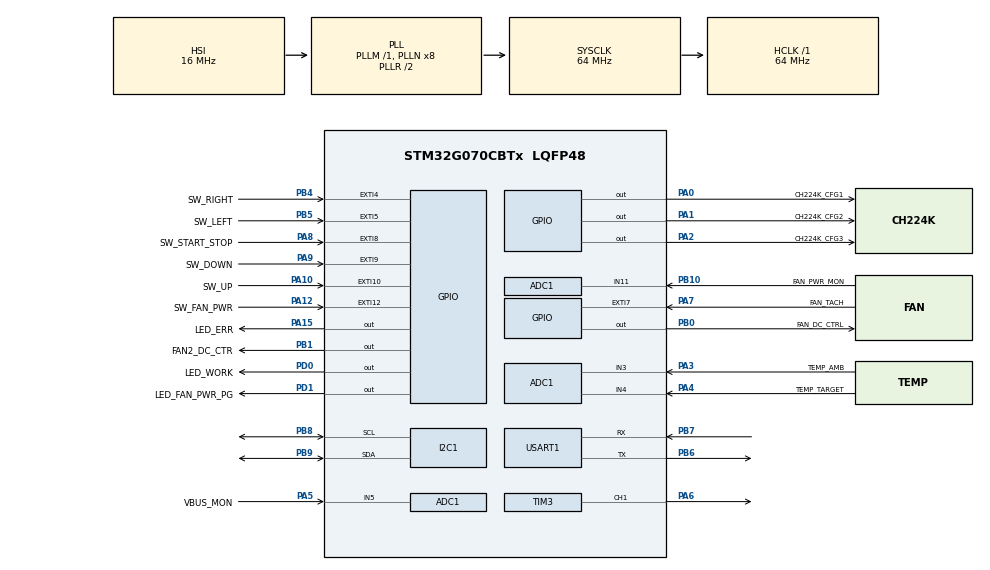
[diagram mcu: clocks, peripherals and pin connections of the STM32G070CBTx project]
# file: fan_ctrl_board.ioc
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ADC1.Channel-1\#ChannelRegularConversion=ADC_CHANNEL_3
ADC1.Channel-2\#ChannelRegularConversion=ADC_CHANNEL_4
ADC1.Channel-3\#ChannelRegularConversion=ADC_CHANNEL_5
ADC1.Channel-4\#ChannelRegularConversion=ADC_CHANNEL_11
ADC1.DiscontinuousConvMode=ENABLE
ADC1.NbrOfConversion=4
ADC1.NbrOfConversionFlag=1
ADC1.Rank-1\#ChannelRegularConversion=1
ADC1.Rank-2\#ChannelRegularConversion=2
ADC1.Rank-3\#ChannelRegularConversion=3
ADC1.Rank-4\#ChannelRegularConversion=4
ADC1.SamplingTime-1\#ChannelRegularConversion=ADC_SAMPLINGTIME_COMMON_1
ADC1.SamplingTime-2\#ChannelRegularConversion=ADC_SAMPLINGTIME_COMMON_1
ADC1.SamplingTime-3\#ChannelRegularConversion=ADC_SAMPLINGTIME_COMMON_1
ADC1.SamplingTime-4\#ChannelRegularConversion=ADC_SAMPLINGTIME_COMMON_1
ADC1.SelectedChannel=ADC_CHANNEL_3|ADC_CHANNEL_4|ADC_CHANNEL_5|ADC_CHANNEL_11
ADC1.master=1
I2C1.Timing=0x10707DBC
Mcu.Family=STM32G0
Mcu.Name=STM32G070CBTx
Mcu.Package=LQFP48
NVIC.ADC1_IRQn=true\:0\:0\:false\:false\:true\:true\:true\:true
NVIC.EXTI4_15_IRQn=true\:0\:0\:false\:false\:true\:true\:true\:true
NVIC.USART1_IRQn=true\:0\:0\:false\:false\:true\:true\:true\:true
PA0.GPIO_Label=CH224K_CFG1
PA0.PinState=GPIO_PIN_SET
PA0.Signal=GPIO_Output
PA1.GPIO_Label=CH224K_CFG2
PA1.Signal=GPIO_Output
PA10.GPIO_Label=SW_UP
PA10.GPIO_ModeDefaultEXTI=GPIO_MODE_IT_RISING_FALLING
PA10.Signal=GPXTI10
PA12\ [PA10].GPIO_Label=SW_FAN_PWR
PA12\ [PA10].GPIO_ModeDefaultEXTI=GPIO_MODE_IT_RISING_FALLING
PA12\ [PA10].Signal=GPXTI12
PA13.Mode=Serial_Wire
PA13.Signal=SYS_SWDIO
PA14-BOOT0.Mode=Serial_Wire
PA14-BOOT0.Signal=SYS_SWCLK
PA15.GPIO_Label=LED_ERR
PA15.Signal=GPIO_Output
PA2.GPIO_Label=CH224K_CFG3
PA2.Signal=GPIO_Output
PA3.GPIO_Label=TEMP_AMB
PA3.Mode=IN3
PA3.Signal=ADC1_IN3
PA4.GPIO_Label=TEMP_TARGET
PA4.Mode=IN4
PA4.Signal=ADC1_IN4
PA5.GPIO_Label=VBUS_MON
PA5.Mode=IN5
PA5.Signal=ADC1_IN5
PA6.Signal=S_TIM3_CH1
PA7.GPIO_Label=FAN_TACH
PA7.GPIO_ModeDefaultEXTI=GPIO_MODE_IT_FALLING
PA7.Signal=GPXTI7
PA8.GPIO_Label=SW_START_STOP 
PA8.GPIO_ModeDefaultEXTI=GPIO_MODE_IT_RISING_FALLING
PA8.Signal=GPXTI8
PA9.GPIO_Label=SW_DOWN
PA9.GPIO_ModeDefaultEXTI=GPIO_MODE_IT_RISING_FALLING
PA9.Signal=GPXTI9
PB0.GPIO_Label=FAN_DC_CTRL
PB0.Signal=GPIO_Output
PB1.GPIO_Label=FAN2_DC_CTR
PB1.Signal=GPIO_Output
PB10.GPIO_Label=FAN_PWR_MON
PB10.Mode=IN11
PB10.Signal=ADC1_IN11
PB4.GPIO_Label=SW_RIGHT
PB4.GPIO_ModeDefaultEXTI=GPIO_MODE_IT_RISING_FALLING
PB4.GPIO_PuPd=GPIO_PULLUP
PB4.Signal=GPXTI4
PB5.GPIO_Label=SW_LEFT
PB5.GPIO_ModeDefaultEXTI=GPIO_MODE_IT_RISING_FALLING
PB5.GPIO_PuPd=GPIO_PULLUP
PB5.Signal=GPXTI5
PB6.Mode=Asynchronous
PB6.Signal=USART1_TX
PB7.Mode=Asynchronous
PB7.Signal=USART1_RX
PB8.GPIO_Pu=GPIO_PULLUP
PB8.Mode=I2C
PB8.Signal=I2C1_SCL
PB9.GPIO_Pu=GPIO_PULLUP
PB9.Mode=I2C
PB9.Signal=I2C1_SDA
PC14-OSC32_IN\ (PC14).Mode=LSE-External-Oscillator
PC14-OSC32_IN\ (PC14).Signal=RCC_OSC32_IN
PC15-OSC32_OUT\ (PC15).Mode=LSE-External-Oscillator
PC15-OSC32_OUT\ (PC15).Signal=RCC_OSC32_OUT
PD0.GPIO_Label=LED_WORK
PD0.Signal=GPIO_Output
PD1.GPIO_Label=LED_FAN_PWR_PG
PD1.Signal=GPIO_Output
PF0-OSC_IN\ (PF0).Mode=HSE-External-Oscillator
PF0-OSC_IN\ (PF0).Signal=RCC_OSC_IN
PF1-OSC_OUT\ (PF1).Mode=HSE-External-Oscillator
PF1-OSC_OUT\ (PF1).Signal=RCC_OSC_OUT
ProjectManager.HeapSize=0x200
ProjectManager.StackSize=0x400
ProjectManager.TargetToolchain=Makefile
RCC.ADCCLockSelection=RCC_ADCCLKSOURCE_PLLADC
RCC.ADCFreq_Value=64000000
RCC.AHBFreq_Value=64000000
RCC.CortexFreq_Value=64000000
RCC.EXTERNAL_CLOCK_VALUE=48000
RCC.HCLKFreq_Value=64000000
RCC.HSE_VALUE=16000000
RCC.HSI_VALUE=16000000
RCC.SYSCLKFreq_VALUE=64000000
RCC.SYSCLKSource=RCC_SYSCLKSOURCE_PLLCLK
RCC.VCOOutputFreq_Value=128000000
SH.S_TIM3_CH1.0=TIM3_CH1,PWM Generation1 CH1
TIM3.Channel-PWM\ Generation1\ CH1=TIM_CHANNEL_1
TIM3.Period=160-1
TIM3.Prescaler=16-1
USART1.VirtualMode-Asynchronous=VM_ASYNC
VP_SYS_VS_DBSignals.Mode=DisableDeadBatterySignals
VP_TIM3_VS_ClockSourceINT.Mode=Internal
board=custom

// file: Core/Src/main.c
/* USER CODE BEGIN Header */
/**
  ******************************************************************************
  * @file           : main.c
  * @brief          : Main program body
  ******************************************************************************
  * @attention
  *
  * Copyright (c) 2024 STMicroelectronics.
  * All rights reserved.
  *
  * This software is licensed under terms that can be found in the LICENSE file
  * in the root directory of this software component.
  * If no LICENSE file comes with this software, it is provided AS-IS.
  *
  ******************************************************************************
  */
/* USER CODE END Header */
#include "main.h"

/* USER CODE BEGIN Includes */
#include "init.h"
/* USER CODE END Includes */

ADC_HandleTypeDef hadc1;

I2C_HandleTypeDef hi2c1;

TIM_HandleTypeDef htim3;

UART_HandleTypeDef huart1;

void SystemClock_Config(void);
static void MX_GPIO_Init(void);
static void MX_ADC1_Init(void);
static void MX_I2C1_Init(void);
static void MX_USART1_UART_Init(void);
static void MX_TIM3_Init(void);

int main(void)
{

  /* MCU Configuration--------------------------------------------------------*/

  /* Reset of all peripherals, Initializes the Flash interface and the Systick. */
  HAL_Init();

  /* Configure the system clock */
  SystemClock_Config();

  /* Initialize all configured peripherals */
  MX_GPIO_Init();
  MX_ADC1_Init();
  MX_I2C1_Init();
  MX_USART1_UART_Init();
  MX_TIM3_Init();
  /* USER CODE BEGIN 2 */
  init();
  /* USER CODE END 2 */

  /* Infinite loop */
  while (1)
  {

  }
}

void SystemClock_Config(void)
{
  RCC_OscInitTypeDef RCC_OscInitStruct = {0};
  RCC_ClkInitTypeDef RCC_ClkInitStruct = {0};

  /** Configure the main internal regulator output voltage
  */
  HAL_PWREx_ControlVoltageScaling(PWR_REGULATOR_VOLTAGE_SCALE1);

  /** Initializes the RCC Oscillators according to the specified parameters
  * in the RCC_OscInitTypeDef structure.
  */
  RCC_OscInitStruct.OscillatorType = RCC_OSCILLATORTYPE_HSI;
  RCC_OscInitStruct.HSIState = RCC_HSI_ON;
  RCC_OscInitStruct.HSIDiv = RCC_HSI_DIV1;
  RCC_OscInitStruct.HSICalibrationValue = RCC_HSICALIBRATION_DEFAULT;
  RCC_OscInitStruct.PLL.PLLState = RCC_PLL_ON;
  RCC_OscInitStruct.PLL.PLLSource = RCC_PLLSOURCE_HSI;
  RCC_OscInitStruct.PLL.PLLM = RCC_PLLM_DIV1;
  RCC_OscInitStruct.PLL.PLLN = 8;
  RCC_OscInitStruct.PLL.PLLP = RCC_PLLP_DIV2;
  RCC_OscInitStruct.PLL.PLLR = RCC_PLLR_DIV2;
  if (HAL_RCC_OscConfig(&RCC_OscInitStruct) != HAL_OK)
  {
    Error_Handler();
  }

  /** Initializes the CPU, AHB and APB buses clocks
  */
  RCC_ClkInitStruct.ClockType = RCC_CLOCKTYPE_HCLK|RCC_CLOCKTYPE_SYSCLK
                              |RCC_CLOCKTYPE_PCLK1;
  RCC_ClkInitStruct.SYSCLKSource = RCC_SYSCLKSOURCE_PLLCLK;
  RCC_ClkInitStruct.AHBCLKDivider = RCC_SYSCLK_DIV1;
  RCC_ClkInitStruct.APB1CLKDivider = RCC_HCLK_DIV1;

  if (HAL_RCC_ClockConfig(&RCC_ClkInitStruct, FLASH_LATENCY_2) != HAL_OK)
  {
    Error_Handler();
  }
}

static void MX_ADC1_Init(void)
{

  ADC_ChannelConfTypeDef sConfig = {0};

  /** Configure the global features of the ADC (Clock, Resolution, Data Alignment and number of conversion)
  */
  hadc1.Instance = ADC1;
  hadc1.Init.ClockPrescaler = ADC_CLOCK_SYNC_PCLK_DIV2;
  hadc1.Init.Resolution = ADC_RESOLUTION_12B;
  hadc1.Init.DataAlign = ADC_DATAALIGN_RIGHT;
  hadc1.Init.ScanConvMode = ADC_SCAN_ENABLE;
  hadc1.Init.EOCSelection = ADC_EOC_SINGLE_CONV;
  hadc1.Init.LowPowerAutoWait = DISABLE;
  hadc1.Init.LowPowerAutoPowerOff = DISABLE;
  hadc1.Init.ContinuousConvMode = DISABLE;
  hadc1.Init.NbrOfConversion = 4;
  hadc1.Init.DiscontinuousConvMode = ENABLE;
  hadc1.Init.ExternalTrigConv = ADC_SOFTWARE_START;
  hadc1.Init.ExternalTrigConvEdge = ADC_EXTERNALTRIGCONVEDGE_NONE;
  hadc1.Init.DMAContinuousRequests = DISABLE;
  hadc1.Init.Overrun = ADC_OVR_DATA_PRESERVED;
  hadc1.Init.SamplingTimeCommon1 = ADC_SAMPLETIME_1CYCLE_5;
  hadc1.Init.SamplingTimeCommon2 = ADC_SAMPLETIME_1CYCLE_5;
  hadc1.Init.OversamplingMode = DISABLE;
  hadc1.Init.TriggerFrequencyMode = ADC_TRIGGER_FREQ_HIGH;
  if (HAL_ADC_Init(&hadc1) != HAL_OK)
  {
    Error_Handler();
  }

  /** Configure Regular Channel
  */
  sConfig.Channel = ADC_CHANNEL_3;
  sConfig.Rank = ADC_REGULAR_RANK_1;
  sConfig.SamplingTime = ADC_SAMPLINGTIME_COMMON_1;
  if (HAL_ADC_ConfigChannel(&hadc1, &sConfig) != HAL_OK)
  {
    Error_Handler();
  }

  /** Configure Regular Channel
  */
  sConfig.Channel = ADC_CHANNEL_4;
  sConfig.Rank = ADC_REGULAR_RANK_2;
  if (HAL_ADC_ConfigChannel(&hadc1, &sConfig) != HAL_OK)
  {
    Error_Handler();
  }

  /** Configure Regular Channel
  */
  sConfig.Channel = ADC_CHANNEL_5;
  sConfig.Rank = ADC_REGULAR_RANK_3;
  if (HAL_ADC_ConfigChannel(&hadc1, &sConfig) != HAL_OK)
  {
    Error_Handler();
  }

  /** Configure Regular Channel
  */
  sConfig.Channel = ADC_CHANNEL_11;
  sConfig.Rank = ADC_REGULAR_RANK_4;
  if (HAL_ADC_ConfigChannel(&hadc1, &sConfig) != HAL_OK)
  {
    Error_Handler();
  }

}

static void MX_I2C1_Init(void)
{

  hi2c1.Instance = I2C1;
  hi2c1.Init.Timing = 0x10707DBC;
  hi2c1.Init.OwnAddress1 = 0;
  hi2c1.Init.AddressingMode = I2C_ADDRESSINGMODE_7BIT;
  hi2c1.Init.DualAddressMode = I2C_DUALADDRESS_DISABLE;
  hi2c1.Init.OwnAddress2 = 0;
  hi2c1.Init.OwnAddress2Masks = I2C_OA2_NOMASK;
  hi2c1.Init.GeneralCallMode = I2C_GENERALCALL_DISABLE;
  hi2c1.Init.NoStretchMode = I2C_NOSTRETCH_DISABLE;
  if (HAL_I2C_Init(&hi2c1) != HAL_OK)
  {
    Error_Handler();
  }

  /** Configure Analogue filter
  */
  if (HAL_I2CEx_ConfigAnalogFilter(&hi2c1, I2C_ANALOGFILTER_ENABLE) != HAL_OK)
  {
    Error_Handler();
  }

  /** Configure Digital filter
  */
  if (HAL_I2CEx_ConfigDigitalFilter(&hi2c1, 0) != HAL_OK)
  {
    Error_Handler();
  }

}

static void MX_TIM3_Init(void)
{

  TIM_ClockConfigTypeDef sClockSourceConfig = {0};
  TIM_MasterConfigTypeDef sMasterConfig = {0};
  TIM_OC_InitTypeDef sConfigOC = {0};

  htim3.Instance = TIM3;
  htim3.Init.Prescaler = 16-1;
  htim3.Init.CounterMode = TIM_COUNTERMODE_UP;
  htim3.Init.Period = 160-1;
  htim3.Init.ClockDivision = TIM_CLOCKDIVISION_DIV1;
  htim3.Init.AutoReloadPreload = TIM_AUTORELOAD_PRELOAD_DISABLE;
  if (HAL_TIM_Base_Init(&htim3) != HAL_OK)
  {
    Error_Handler();
  }
  sClockSourceConfig.ClockSource = TIM_CLOCKSOURCE_INTERNAL;
  if (HAL_TIM_ConfigClockSource(&htim3, &sClockSourceConfig) != HAL_OK)
  {
    Error_Handler();
  }
  if (HAL_TIM_PWM_Init(&htim3) != HAL_OK)
  {
    Error_Handler();
  }
  sMasterConfig.MasterOutputTrigger = TIM_TRGO_RESET;
  sMasterConfig.MasterSlaveMode = TIM_MASTERSLAVEMODE_DISABLE;
  if (HAL_TIMEx_MasterConfigSynchronization(&htim3, &sMasterConfig) != HAL_OK)
  {
    Error_Handler();
  }
  sConfigOC.OCMode = TIM_OCMODE_PWM1;
  sConfigOC.Pulse = 0;
  sConfigOC.OCPolarity = TIM_OCPOLARITY_HIGH;
  sConfigOC.OCFastMode = TIM_OCFAST_DISABLE;
  if (HAL_TIM_PWM_ConfigChannel(&htim3, &sConfigOC, TIM_CHANNEL_1) != HAL_OK)
  {
    Error_Handler();
  }
  HAL_TIM_MspPostInit(&htim3);

}

static void MX_USART1_UART_Init(void)
{

  huart1.Instance = USART1;
  huart1.Init.BaudRate = 115200;
  huart1.Init.WordLength = UART_WORDLENGTH_8B;
  huart1.Init.StopBits = UART_STOPBITS_1;
  huart1.Init.Parity = UART_PARITY_NONE;
  huart1.Init.Mode = UART_MODE_TX_RX;
  huart1.Init.HwFlowCtl = UART_HWCONTROL_NONE;
  huart1.Init.OverSampling = UART_OVERSAMPLING_16;
  huart1.Init.OneBitSampling = UART_ONE_BIT_SAMPLE_DISABLE;
  huart1.Init.ClockPrescaler = UART_PRESCALER_DIV1;
  huart1.AdvancedInit.AdvFeatureInit = UART_ADVFEATURE_NO_INIT;
  if (HAL_UART_Init(&huart1) != HAL_OK)
  {
    Error_Handler();
  }
  if (HAL_UARTEx_SetTxFifoThreshold(&huart1, UART_TXFIFO_THRESHOLD_1_8) != HAL_OK)
  {
    Error_Handler();
  }
  if (HAL_UARTEx_SetRxFifoThreshold(&huart1, UART_RXFIFO_THRESHOLD_1_8) != HAL_OK)
  {
    Error_Handler();
  }
  if (HAL_UARTEx_DisableFifoMode(&huart1) != HAL_OK)
  {
    Error_Handler();
  }

}

static void MX_GPIO_Init(void)
{
  GPIO_InitTypeDef GPIO_InitStruct = {0};

  /* GPIO Ports Clock Enable */
  __HAL_RCC_GPIOC_CLK_ENABLE();
  __HAL_RCC_GPIOF_CLK_ENABLE();
  __HAL_RCC_GPIOA_CLK_ENABLE();
  __HAL_RCC_GPIOB_CLK_ENABLE();
  __HAL_RCC_GPIOD_CLK_ENABLE();

  /*Configure GPIO pin Output Level */
  HAL_GPIO_WritePin(CH224K_CFG1_GPIO_Port, CH224K_CFG1_Pin, GPIO_PIN_SET);

  /*Configure GPIO pin Output Level */
  HAL_GPIO_WritePin(GPIOA, CH224K_CFG2_Pin|CH224K_CFG3_Pin|LED_ERR_Pin, GPIO_PIN_RESET);

  /*Configure GPIO pin Output Level */
  HAL_GPIO_WritePin(GPIOB, FAN_DC_CTRL_Pin|FAN2_DC_CTR_Pin, GPIO_PIN_RESET);

  /*Configure GPIO pin Output Level */
  HAL_GPIO_WritePin(GPIOD, LED_WORK_Pin|LED_FAN_PWR_PG_Pin, GPIO_PIN_RESET);

  /*Configure GPIO pins : CH224K_CFG1_Pin CH224K_CFG2_Pin CH224K_CFG3_Pin LED_ERR_Pin */
  GPIO_InitStruct.Pin = CH224K_CFG1_Pin|CH224K_CFG2_Pin|CH224K_CFG3_Pin|LED_ERR_Pin;
  GPIO_InitStruct.Mode = GPIO_MODE_OUTPUT_PP;
  GPIO_InitStruct.Pull = GPIO_NOPULL;
  GPIO_InitStruct.Speed = GPIO_SPEED_FREQ_LOW;
  HAL_GPIO_Init(GPIOA, &GPIO_InitStruct);

  /*Configure GPIO pin : FAN_TACH_Pin */
  GPIO_InitStruct.Pin = FAN_TACH_Pin;
  GPIO_InitStruct.Mode = GPIO_MODE_IT_FALLING;
  GPIO_InitStruct.Pull = GPIO_NOPULL;
  HAL_GPIO_Init(FAN_TACH_GPIO_Port, &GPIO_InitStruct);

  /*Configure GPIO pins : FAN_DC_CTRL_Pin FAN2_DC_CTR_Pin */
  GPIO_InitStruct.Pin = FAN_DC_CTRL_Pin|FAN2_DC_CTR_Pin;
  GPIO_InitStruct.Mode = GPIO_MODE_OUTPUT_PP;
  GPIO_InitStruct.Pull = GPIO_NOPULL;
  GPIO_InitStruct.Speed = GPIO_SPEED_FREQ_LOW;
  HAL_GPIO_Init(GPIOB, &GPIO_InitStruct);

  /*Configure GPIO pins : SW_START_STOP_Pin SW_DOWN_Pin SW_UP_Pin SW_FAN_PWR_Pin */
  GPIO_InitStruct.Pin = SW_START_STOP_Pin|SW_DOWN_Pin|SW_UP_Pin|SW_FAN_PWR_Pin;
  GPIO_InitStruct.Mode = GPIO_MODE_IT_RISING_FALLING;
  GPIO_InitStruct.Pull = GPIO_NOPULL;
  HAL_GPIO_Init(GPIOA, &GPIO_InitStruct);

  /*Configure GPIO pins : LED_WORK_Pin LED_FAN_PWR_PG_Pin */
  GPIO_InitStruct.Pin = LED_WORK_Pin|LED_FAN_PWR_PG_Pin;
  GPIO_InitStruct.Mode = GPIO_MODE_OUTPUT_PP;
  GPIO_InitStruct.Pull = GPIO_NOPULL;
  GPIO_InitStruct.Speed = GPIO_SPEED_FREQ_LOW;
  HAL_GPIO_Init(GPIOD, &GPIO_InitStruct);

  /*Configure GPIO pins : SW_RIGHT_Pin SW_LEFT_Pin */
  GPIO_InitStruct.Pin = SW_RIGHT_Pin|SW_LEFT_Pin;
  GPIO_InitStruct.Mode = GPIO_MODE_IT_RISING_FALLING;
  GPIO_InitStruct.Pull = GPIO_PULLUP;
  HAL_GPIO_Init(GPIOB, &GPIO_InitStruct);

  /* EXTI interrupt init*/
  HAL_NVIC_SetPriority(EXTI4_15_IRQn, 0, 0);
  HAL_NVIC_EnableIRQ(EXTI4_15_IRQn);

}

void Error_Handler(void)
{
  __disable_irq();
  while (1)
  {
  }
}
